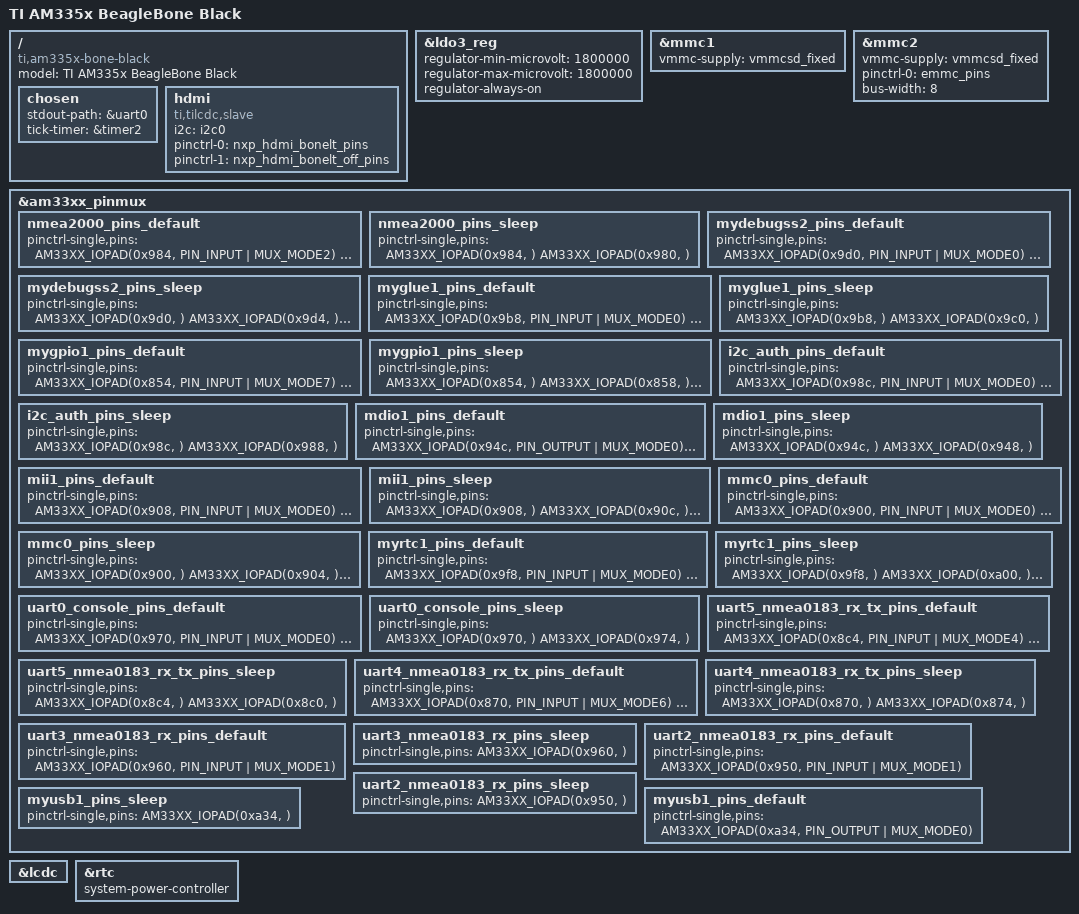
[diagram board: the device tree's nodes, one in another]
/*
 * Copyright (C) 2012 Texas Instruments Incorporated - http://www.ti.com/
 *
 * This program is free software; you can redistribute it and/or modify
 * it under the terms of the GNU General Public License version 2 as
 * published by the Free Software Foundation.
 */
/dts-v1/;

#include "am33xx.dtsi"
#include "am335x-bone-common.dtsi"

/ {
	model = "TI AM335x BeagleBone Black";
	compatible = "ti,am335x-bone-black", "ti,am335x-bone", "ti,am33xx";
	chosen {
		stdout-path = &uart0;
		tick-timer = &timer2;
	};
};

&ldo3_reg {
	regulator-min-microvolt = <1800000>;
	regulator-max-microvolt = <1800000>;
	regulator-always-on;
};

&mmc1 {
	vmmc-supply = <&vmmcsd_fixed>;
};

&mmc2 {
	vmmc-supply = <&vmmcsd_fixed>;
	pinctrl-names = "default";
	pinctrl-0 = <&emmc_pins>;
	bus-width = <8>;
	status = "okay";
};

/* This file was auto-generated by TI PinMux on 2/23/2020 at 6:42:30 PM. */
/* This file should only be used as a reference. Some pins/peripherals, */
/* depending on your use case, may need additional configuration. */

/* Some or all the pins from the following groups are not used by device tree 
   myadc1
   myglue1
   myosc1
   myusb1
*/

&am33xx_pinmux {
	nmea2000_pins_default: nmea2000_pins_default {
		pinctrl-single,pins = <
			AM33XX_IOPAD(0x984, PIN_INPUT | MUX_MODE2) /* (D15) uart1_txd.dcan1_rx */
			AM33XX_IOPAD(0x980, PIN_OUTPUT | MUX_MODE2) /* (D16) uart1_rxd.dcan1_tx */
		>;
	};

	/* Optional sleep pin settings. Must manually enter values in the below skeleton. */
	nmea2000_pins_sleep: nmea2000_pins_sleep {
		pinctrl-single,pins = <
			AM33XX_IOPAD(0x984,  ) /* (D15) uart1_txd.dcan1_rx */
			AM33XX_IOPAD(0x980,  ) /* (D16) uart1_rxd.dcan1_tx */
		>;
	};

	mydebugss2_pins_default: mydebugss2_pins_default {
		pinctrl-single,pins = <
			AM33XX_IOPAD(0x9d0, PIN_INPUT | MUX_MODE0) /* (C11) TMS.TMS */
			AM33XX_IOPAD(0x9d4, PIN_INPUT | MUX_MODE0) /* (B11) TDI.TDI */
			AM33XX_IOPAD(0x9d8, PIN_OUTPUT | MUX_MODE0) /* (A11) TDO.TDO */
			AM33XX_IOPAD(0x9dc, PIN_INPUT | MUX_MODE0) /* (A12) TCK.TCK */
			AM33XX_IOPAD(0x9e0, PIN_INPUT | MUX_MODE0) /* (B10) nTRST.nTRST */
			AM33XX_IOPAD(0x9e4, PIN_INPUT | MUX_MODE0) /* (C14) EMU0.EMU0 */
			AM33XX_IOPAD(0x9e8, PIN_INPUT | MUX_MODE0) /* (B14) EMU1.EMU1 */
			AM33XX_IOPAD(0x9b0, PIN_INPUT | MUX_MODE6) /* (A15) xdma_event_intr0.EMU2 */
			AM33XX_IOPAD(0x9b4, PIN_INPUT | MUX_MODE6) /* (D14) xdma_event_intr1.EMU3 */
			AM33XX_IOPAD(0x9ac, PIN_INPUT | MUX_MODE4) /* (A14) mcasp0_ahclkx.EMU4 */
		>;
	};

	/* Optional sleep pin settings. Must manually enter values in the below skeleton. */
	mydebugss2_pins_sleep: mydebugss2_pins_sleep {
		pinctrl-single,pins = <
			AM33XX_IOPAD(0x9d0,  ) /* (C11) TMS.TMS */
			AM33XX_IOPAD(0x9d4,  ) /* (B11) TDI.TDI */
			AM33XX_IOPAD(0x9d8,  ) /* (A11) TDO.TDO */
			AM33XX_IOPAD(0x9dc,  ) /* (A12) TCK.TCK */
			AM33XX_IOPAD(0x9e0,  ) /* (B10) nTRST.nTRST */
			AM33XX_IOPAD(0x9e4,  ) /* (C14) EMU0.EMU0 */
			AM33XX_IOPAD(0x9e8,  ) /* (B14) EMU1.EMU1 */
			AM33XX_IOPAD(0x9b0,  ) /* (A15) xdma_event_intr0.EMU2 */
			AM33XX_IOPAD(0x9b4,  ) /* (D14) xdma_event_intr1.EMU3 */
			AM33XX_IOPAD(0x9ac,  ) /* (A14) mcasp0_ahclkx.EMU4 */
		>;
	};

	myglue1_pins_default: myglue1_pins_default {
		pinctrl-single,pins = <
			AM33XX_IOPAD(0x9b8, PIN_INPUT | MUX_MODE0) /* (A10) nRESETIN_OUT.nRESETIN_OUT */
			AM33XX_IOPAD(0x9c0, PIN_INPUT | MUX_MODE0) /* (B18) nNMI.nNMI */
		>;
	};

	/* Optional sleep pin settings. Must manually enter values in the below skeleton. */
	myglue1_pins_sleep: myglue1_pins_sleep {
		pinctrl-single,pins = <
			AM33XX_IOPAD(0x9b8,  ) /* (A10) nRESETIN_OUT.nRESETIN_OUT */
			AM33XX_IOPAD(0x9c0,  ) /* (B18) nNMI.nNMI */
		>;
	};

	mygpio1_pins_default: mygpio1_pins_default {
		pinctrl-single,pins = <
			AM33XX_IOPAD(0x854, PIN_INPUT | MUX_MODE7) /* (V15) gpmc_a5.gpio1[21] */
			AM33XX_IOPAD(0x858, PIN_INPUT | MUX_MODE7) /* (U15) gpmc_a6.gpio1[22] */
			AM33XX_IOPAD(0x864, PIN_INPUT | MUX_MODE7) /* (U16) gpmc_a9.gpio1[25] */
			AM33XX_IOPAD(0x868, PIN_INPUT | MUX_MODE7) /* (T16) gpmc_a10.gpio1[26] */
		>;
	};

	/* Optional sleep pin settings. Must manually enter values in the below skeleton. */
	mygpio1_pins_sleep: mygpio1_pins_sleep {
		pinctrl-single,pins = <
			AM33XX_IOPAD(0x854,  ) /* (V15) gpmc_a5.gpio1[21] */
			AM33XX_IOPAD(0x858,  ) /* (U15) gpmc_a6.gpio1[22] */
			AM33XX_IOPAD(0x864,  ) /* (U16) gpmc_a9.gpio1[25] */
			AM33XX_IOPAD(0x868,  ) /* (T16) gpmc_a10.gpio1[26] */
		>;
	};

	i2c_auth_pins_default: i2c_auth_pins_default {
		pinctrl-single,pins = <
			AM33XX_IOPAD(0x98c, PIN_INPUT | MUX_MODE0) /* (C16) I2C0_SCL.I2C0_SCL */
			AM33XX_IOPAD(0x988, PIN_INPUT | MUX_MODE0) /* (C17) I2C0_SDA.I2C0_SDA */
		>;
	};

	/* Optional sleep pin settings. Must manually enter values in the below skeleton. */
	i2c_auth_pins_sleep: i2c_auth_pins_sleep {
		pinctrl-single,pins = <
			AM33XX_IOPAD(0x98c,  ) /* (C16) I2C0_SCL.I2C0_SCL */
			AM33XX_IOPAD(0x988,  ) /* (C17) I2C0_SDA.I2C0_SDA */
		>;
	};

	mdio1_pins_default: mdio1_pins_default {
		pinctrl-single,pins = <
			AM33XX_IOPAD(0x94c, PIN_OUTPUT | MUX_MODE0) /* (M18) mdio_clk.mdio_clk */
			AM33XX_IOPAD(0x948, PIN_INPUT | MUX_MODE0) /* (M17) mdio_data.mdio_data */
		>;
	};

	/* Optional sleep pin settings. Must manually enter values in the below skeleton. */
	mdio1_pins_sleep: mdio1_pins_sleep {
		pinctrl-single,pins = <
			AM33XX_IOPAD(0x94c,  ) /* (M18) mdio_clk.mdio_clk */
			AM33XX_IOPAD(0x948,  ) /* (M17) mdio_data.mdio_data */
		>;
	};

	mii1_pins_default: mii1_pins_default {
		pinctrl-single,pins = <
			AM33XX_IOPAD(0x908, PIN_INPUT | MUX_MODE0) /* (H16) gmii1_col.gmii1_col */
			AM33XX_IOPAD(0x90c, PIN_INPUT | MUX_MODE0) /* (H17) gmii1_crs.gmii1_crs */
			AM33XX_IOPAD(0x910, PIN_INPUT | MUX_MODE0) /* (J15) gmii1_rxer.gmii1_rxer */
			AM33XX_IOPAD(0x914, PIN_OUTPUT | MUX_MODE0) /* (J16) gmii1_txen.gmii1_txen */
			AM33XX_IOPAD(0x918, PIN_INPUT | MUX_MODE0) /* (J17) gmii1_rxdv.gmii1_rxdv */
			AM33XX_IOPAD(0x92c, PIN_INPUT | MUX_MODE0) /* (K18) gmii1_txclk.gmii1_txclk */
			AM33XX_IOPAD(0x930, PIN_INPUT | MUX_MODE0) /* (L18) gmii1_rxclk.gmii1_rxclk */
			AM33XX_IOPAD(0x928, PIN_OUTPUT | MUX_MODE0) /* (K17) gmii1_txd0.gmii1_txd0 */
			AM33XX_IOPAD(0x924, PIN_OUTPUT | MUX_MODE0) /* (K16) gmii1_txd1.gmii1_txd1 */
			AM33XX_IOPAD(0x920, PIN_OUTPUT | MUX_MODE0) /* (K15) gmii1_txd2.gmii1_txd2 */
			AM33XX_IOPAD(0x91c, PIN_OUTPUT | MUX_MODE0) /* (J18) gmii1_txd3.gmii1_txd3 */
			AM33XX_IOPAD(0x940, PIN_INPUT | MUX_MODE0) /* (M16) gmii1_rxd0.gmii1_rxd0 */
			AM33XX_IOPAD(0x93c, PIN_INPUT | MUX_MODE0) /* (L15) gmii1_rxd1.gmii1_rxd1 */
			AM33XX_IOPAD(0x938, PIN_INPUT | MUX_MODE0) /* (L16) gmii1_rxd2.gmii1_rxd2 */
			AM33XX_IOPAD(0x934, PIN_INPUT | MUX_MODE0) /* (L17) gmii1_rxd3.gmii1_rxd3 */
		>;
	};

	/* Optional sleep pin settings. Must manually enter values in the below skeleton. */
	mii1_pins_sleep: mii1_pins_sleep {
		pinctrl-single,pins = <
			AM33XX_IOPAD(0x908,  ) /* (H16) gmii1_col.gmii1_col */
			AM33XX_IOPAD(0x90c,  ) /* (H17) gmii1_crs.gmii1_crs */
			AM33XX_IOPAD(0x910,  ) /* (J15) gmii1_rxer.gmii1_rxer */
			AM33XX_IOPAD(0x914,  ) /* (J16) gmii1_txen.gmii1_txen */
			AM33XX_IOPAD(0x918,  ) /* (J17) gmii1_rxdv.gmii1_rxdv */
			AM33XX_IOPAD(0x92c,  ) /* (K18) gmii1_txclk.gmii1_txclk */
			AM33XX_IOPAD(0x930,  ) /* (L18) gmii1_rxclk.gmii1_rxclk */
			AM33XX_IOPAD(0x928,  ) /* (K17) gmii1_txd0.gmii1_txd0 */
			AM33XX_IOPAD(0x924,  ) /* (K16) gmii1_txd1.gmii1_txd1 */
			AM33XX_IOPAD(0x920,  ) /* (K15) gmii1_txd2.gmii1_txd2 */
			AM33XX_IOPAD(0x91c,  ) /* (J18) gmii1_txd3.gmii1_txd3 */
			AM33XX_IOPAD(0x940,  ) /* (M16) gmii1_rxd0.gmii1_rxd0 */
			AM33XX_IOPAD(0x93c,  ) /* (L15) gmii1_rxd1.gmii1_rxd1 */
			AM33XX_IOPAD(0x938,  ) /* (L16) gmii1_rxd2.gmii1_rxd2 */
			AM33XX_IOPAD(0x934,  ) /* (L17) gmii1_rxd3.gmii1_rxd3 */
		>;
	};

	mmc0_pins_default: mmc0_pins_default {
		pinctrl-single,pins = <
			AM33XX_IOPAD(0x900, PIN_INPUT | MUX_MODE0) /* (G17) mmc0_clk.mmc0_clk */
			AM33XX_IOPAD(0x904, PIN_INPUT | MUX_MODE0) /* (G18) mmc0_cmd.mmc0_cmd */
			AM33XX_IOPAD(0x8fc, PIN_INPUT | MUX_MODE0) /* (G16) mmc0_dat0.mmc0_dat0 */
			AM33XX_IOPAD(0x8f8, PIN_INPUT | MUX_MODE0) /* (G15) mmc0_dat1.mmc0_dat1 */
			AM33XX_IOPAD(0x8f4, PIN_INPUT | MUX_MODE0) /* (F18) mmc0_dat2.mmc0_dat2 */
			AM33XX_IOPAD(0x8f0, PIN_INPUT | MUX_MODE0) /* (F17) mmc0_dat3.mmc0_dat3 */
			AM33XX_IOPAD(0x990, PIN_INPUT | MUX_MODE4) /* (A13) mcasp0_aclkx.mmc0_sdcd */
		>;
	};

	/* Optional sleep pin settings. Must manually enter values in the below skeleton. */
	mmc0_pins_sleep: mmc0_pins_sleep {
		pinctrl-single,pins = <
			AM33XX_IOPAD(0x900,  ) /* (G17) mmc0_clk.mmc0_clk */
			AM33XX_IOPAD(0x904,  ) /* (G18) mmc0_cmd.mmc0_cmd */
			AM33XX_IOPAD(0x8fc,  ) /* (G16) mmc0_dat0.mmc0_dat0 */
			AM33XX_IOPAD(0x8f8,  ) /* (G15) mmc0_dat1.mmc0_dat1 */
			AM33XX_IOPAD(0x8f4,  ) /* (F18) mmc0_dat2.mmc0_dat2 */
			AM33XX_IOPAD(0x8f0,  ) /* (F17) mmc0_dat3.mmc0_dat3 */
			AM33XX_IOPAD(0x990,  ) /* (A13) mcasp0_aclkx.mmc0_sdcd */
		>;
	};

	myrtc1_pins_default: myrtc1_pins_default {
		pinctrl-single,pins = <
			AM33XX_IOPAD(0x9f8, PIN_INPUT | MUX_MODE0) /* (B5) RTC_PORz.RTC_PORz */
			AM33XX_IOPAD(0xa00, PIN_OUTPUT | MUX_MODE0) /* (C5) EXT_WAKEUP.EXT_WAKEUP */
			AM33XX_IOPAD(0x9fc, PIN_INPUT | MUX_MODE0) /* (C6) PMIC_POWER_EN.PMIC_POWER_EN */
			AM33XX_IOPAD(0xa04, PIN_INPUT | MUX_MODE0) /* (B4) ENZ_KALDO_1P8V.ENZ_KALDO_1P8V */
		>;
	};

	/* Optional sleep pin settings. Must manually enter values in the below skeleton. */
	myrtc1_pins_sleep: myrtc1_pins_sleep {
		pinctrl-single,pins = <
			AM33XX_IOPAD(0x9f8,  ) /* (B5) RTC_PORz.RTC_PORz */
			AM33XX_IOPAD(0xa00,  ) /* (C5) EXT_WAKEUP.EXT_WAKEUP */
			AM33XX_IOPAD(0x9fc,  ) /* (C6) PMIC_POWER_EN.PMIC_POWER_EN */
			AM33XX_IOPAD(0xa04,  ) /* (B4) ENZ_KALDO_1P8V.ENZ_KALDO_1P8V */
		>;
	};

	uart0_console_pins_default: uart0_console_pins_default {
		pinctrl-single,pins = <
			AM33XX_IOPAD(0x970, PIN_INPUT | MUX_MODE0) /* (E15) uart0_rxd.uart0_rxd */
			AM33XX_IOPAD(0x974, PIN_OUTPUT | MUX_MODE0) /* (E16) uart0_txd.uart0_txd */
		>;
	};

	/* Optional sleep pin settings. Must manually enter values in the below skeleton. */
	uart0_console_pins_sleep: uart0_console_pins_sleep {
		pinctrl-single,pins = <
			AM33XX_IOPAD(0x970,  ) /* (E15) uart0_rxd.uart0_rxd */
			AM33XX_IOPAD(0x974,  ) /* (E16) uart0_txd.uart0_txd */
		>;
	};

	uart5_nmea0183_rx_tx_pins_default: uart5_nmea0183_rx_tx_pins_default {
		pinctrl-single,pins = <
			AM33XX_IOPAD(0x8c4, PIN_INPUT | MUX_MODE4) /* (U2) lcd_data9.uart5_rxd */
			AM33XX_IOPAD(0x8c0, PIN_OUTPUT | MUX_MODE4) /* (U1) lcd_data8.uart5_txd */
		>;
	};

	/* Optional sleep pin settings. Must manually enter values in the below skeleton. */
	uart5_nmea0183_rx_tx_pins_sleep: uart5_nmea0183_rx_tx_pins_sleep {
		pinctrl-single,pins = <
			AM33XX_IOPAD(0x8c4,  ) /* (U2) lcd_data9.uart5_rxd */
			AM33XX_IOPAD(0x8c0,  ) /* (U1) lcd_data8.uart5_txd */
		>;
	};

	uart4_nmea0183_rx_tx_pins_default: uart4_nmea0183_rx_tx_pins_default {
		pinctrl-single,pins = <
			AM33XX_IOPAD(0x870, PIN_INPUT | MUX_MODE6) /* (T17) gpmc_wait0.uart4_rxd */
			AM33XX_IOPAD(0x874, PIN_OUTPUT | MUX_MODE6) /* (U17) gpmc_wpn.uart4_txd */
		>;
	};

	/* Optional sleep pin settings. Must manually enter values in the below skeleton. */
	uart4_nmea0183_rx_tx_pins_sleep: uart4_nmea0183_rx_tx_pins_sleep {
		pinctrl-single,pins = <
			AM33XX_IOPAD(0x870,  ) /* (T17) gpmc_wait0.uart4_rxd */
			AM33XX_IOPAD(0x874,  ) /* (U17) gpmc_wpn.uart4_txd */
		>;
	};

	uart3_nmea0183_rx_pins_default: uart3_nmea0183_rx_pins_default {
		pinctrl-single,pins = <
			AM33XX_IOPAD(0x960, PIN_INPUT | MUX_MODE1) /* (C15) spi0_cs1.uart3_rxd */
		>;
	};

	/* Optional sleep pin settings. Must manually enter values in the below skeleton. */
	uart3_nmea0183_rx_pins_sleep: uart3_nmea0183_rx_pins_sleep {
		pinctrl-single,pins = <
			AM33XX_IOPAD(0x960,  ) /* (C15) spi0_cs1.uart3_rxd */
		>;
	};

	uart2_nmea0183_rx_pins_default: uart2_nmea0183_rx_pins_default {
		pinctrl-single,pins = <
			AM33XX_IOPAD(0x950, PIN_INPUT | MUX_MODE1) /* (A17) spi0_sclk.uart2_rxd */
		>;
	};

	/* Optional sleep pin settings. Must manually enter values in the below skeleton. */
	uart2_nmea0183_rx_pins_sleep: uart2_nmea0183_rx_pins_sleep {
		pinctrl-single,pins = <
			AM33XX_IOPAD(0x950,  ) /* (A17) spi0_sclk.uart2_rxd */
		>;
	};

	myusb1_pins_default: myusb1_pins_default {
		pinctrl-single,pins = <
			AM33XX_IOPAD(0xa34, PIN_OUTPUT | MUX_MODE0) /* (F15) USB1_DRVVBUS.USB1_DRVVBUS */
		>;
	};

	/* Optional sleep pin settings. Must manually enter values in the below skeleton. */
	myusb1_pins_sleep: myusb1_pins_sleep {
		pinctrl-single,pins = <
			AM33XX_IOPAD(0xa34,  ) /* (F15) USB1_DRVVBUS.USB1_DRVVBUS */
		>;
	};

};

&lcdc {
	status = "okay";
};

/ {
	hdmi {
		compatible = "ti,tilcdc,slave";
		i2c = <&i2c0>;
		pinctrl-names = "default", "off";
		pinctrl-0 = <&nxp_hdmi_bonelt_pins>;
		pinctrl-1 = <&nxp_hdmi_bonelt_off_pins>;
		status = "okay";
	};
};

&rtc {
	system-power-controller;
};
